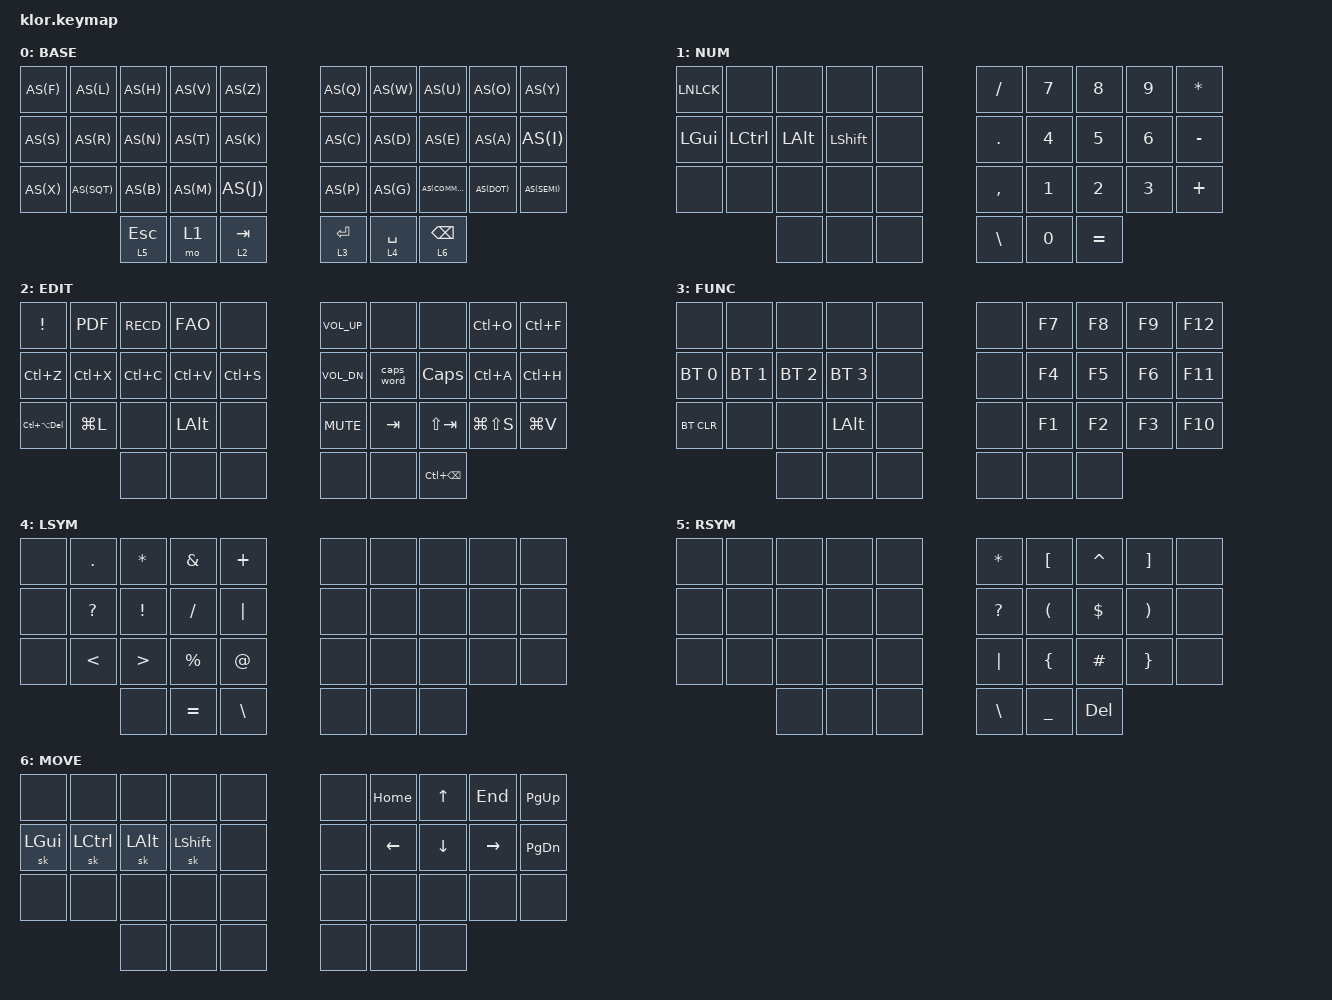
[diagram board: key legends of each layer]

//                     █         █    █            ▄▄▄▀▀▀▀▀▀▄▄▄        █▀▀▀▀▀▀▀▀▀▀█
//                     █        █     █          ▄▀            ▀▄      █          █
//                     █       █      █        ▄▀                ▀▄    █          █
//                     █      █       █        █                  █    █          █
//                     █     █        █       █                    █   █          █
//                     █    █         █       █                    █   █▄▄▄▄▄▄▄▄▄▄█
//                     █   █ █        █       █                    █   █      █
//                     █  █   █       █        █                  █    █       █
//                     █ █     █      █        ▀▄                ▄▀    █        █
//                     ██       █     █          ▀▄            ▄▀      █         █
//                     █         █    █▄▄▄▄▄▄▄▄    ▀▀▀▄▄▄▄▄▄▀▀▀        █          █
//
// ▄▄▄▄▄▄▄▄▄▄▄▄▄▄▄▄▄▄▄▄▄▄▄▄▄▄▄▄▄▄▄▄▄▄▄▄▄▄▄▄▄▄▄▄▄▄▄▄▄▄▄▄▄▄▄▄▄▄▄▄▄▄▄▄▄▄▄▄▄▄▄▄▄▄▄▄▄▄▄▄▄▄▄▄▄▄▄▄▄▄▄▄▄▄▄▄▄▄▄▄▄▄▄▄▄▄▄▄▄▄▄▄▄▄▄▄▄▄▄▄▄▄▄▄▄
       
#include <behaviors.dtsi>
#include <dt-bindings/zmk/keys.h>
#include <dt-bindings/zmk/bt.h>
#include <dt-bindings/zmk/outputs.h>
#include <dt-bindings/zmk/ext_power.h>
#include <dt-bindings/zmk/rgb.h>


#define BASE 0
#define NUM  1
#define FUNC 2
#define EDIT 3
#define LSYM 4
#define RSYM 5
#define MOVE 6
#define AS(keycode) &as LS(keycode) keycode   // Autoshift Macro


&lt {
    tapping_term_ms = <200>;
    quick_tap_ms = <150>;
    flavor = "tap-preferred";
};

/ {
    behaviors {
        as: auto_shift {
            compatible = "zmk,behavior-hold-tap";
            #binding-cells = <2>;
            tapping_term_ms = <200>;
            quick_tap_ms = <150>;
            flavor = "tap-preferred";
            bindings = <&kp>, <&kp>;
        };
    };



        keymap {
                compatible = "zmk,keymap";


// ▄▄▄▄▄▄▄▄▄▄▄▄▄▄▄▄▄▄▄▄▄▄▄▄▄▄▄▄▄▄▄▄▄▄▄▄▄▄▄▄▄▄▄▄▄▄▄▄▄▄▄▄▄▄▄▄▄▄▄▄▄▄▄▄▄▄▄▄▄▄▄▄▄▄▄▄▄▄▄▄▄▄▄▄▄▄▄▄▄▄▄▄▄▄▄▄▄▄▄▄▄▄▄▄▄▄▄▄▄▄▄▄▄▄▄▄▄▄▄▄▄▄▄▄▄


                BASE {
// ┌───────────────────────────────────────────────────────────┐
display-name = "BASE"                                          ;        
// └───────────────────────────────────────────────────────────┘
/*  ┌─────────┬─────────┬─────────┬─────────┬─────────┐                    ┌─────────┬─────────┬─────────┬─────────┬─────────┐
    │    F    │    L    │    H    │    V    │    Z    │                    │    Q    |    W    |    U    |    O    |    Y    │   
    |─────────┼─────────┼─────────┼─────────┼─────────┤                    ├─────────┼─────────┼─────────┼─────────┼─────────|
    │    S    |    R    |    N    |    T    |    K    │                    │    C    |    D    |    E    |    A    |    I    │
    |─────────┼─────────┼─────────┼─────────┼─────────┤╭────────╮╭────────╮├─────────┼─────────┼─────────┼─────────┼─────────|
    │    X    |    '    |    B    |    M    |    J    ││  ENC2  ││  ENC1  ││    K    │    M    │    ,    │    .    │    /    │
    |─────────┴─────────┼─────────┼─────────┼─────────┼╰────────╯╰────────╯┼─────────┼─────────┼─────────┼─────────┴─────────┴
                        │ L5/ESC  |   L1    | L3/TAB  │         ││         │  ENTER  │  RAISE  │  BSPCE  │  
                        └─────────┴─────────┴─────────┴─────────┘└─────────┴─────────┴─────────┴─────────┘ */ 
 bindings = <
        AS(F) AS(L)   AS(H) AS(V) AS(Z)   AS(Q) AS(W)  AS(U)     AS(O)   AS(Y)   
        AS(S) AS(R)   AS(N) AS(T) AS(K)   AS(C) AS(D)  AS(E)     AS(A)   AS(I)   
        AS(X) AS(SQT) AS(B) AS(M) AS(J)   AS(P) AS(G)  AS(COMMA) AS(DOT) AS(SEMI) 
              &lt 5 ESC &mo 1 &lt 2 TAB  &lt 3 ENTER &lt 4 SPACE &lt 6 BSPC    
                        >;
                };

// ▄▄▄▄▄▄▄▄▄▄▄▄▄▄▄▄▄▄▄▄▄▄▄▄▄▄▄▄▄▄▄▄▄▄▄▄▄▄▄▄▄▄▄▄▄▄▄▄▄▄▄▄▄▄▄▄▄▄▄▄▄▄▄▄▄▄▄▄▄▄▄▄▄▄▄▄▄▄▄▄▄▄▄▄▄▄▄▄▄▄▄▄▄▄▄▄▄▄▄▄▄▄▄▄▄▄▄▄▄▄▄▄▄▄▄▄▄▄▄▄▄▄▄▄▄


                NUM {
// ┌───────────────────────────────────────────────────────────┐
display-name = "NUM"                                           ;      
// └───────────────────────────────────────────────────────────┘
/*  ┌─────────┬─────────┬─────────┬─────────┬─────────┐                    ┌─────────┬─────────┬─────────┬─────────┬─────────┐
    │   NLK   │         │         │         │         │                    │    /    |    7    |    8    |    9    |    *    │   
    |─────────┼─────────┼─────────┼─────────┼─────────┤                    ├─────────┼─────────┼─────────┼─────────┼─────────|
    │   GUI   |   CTL   |   ALT   |   SFT   │         │                    │    .    |    4    |    5    |    6    |    -    │
    |─────────┼─────────┼─────────┼─────────┼─────────┤╭────────╮╭────────╮├─────────┼─────────┼─────────┼─────────┼─────────|
    │         │         |         |         |         ││  ENC2  ││  ENC1  ││    ,    |    1    |    2    |    3    |    +    │
    |─────────┴─────────┼─────────┼─────────┼─────────┼╰────────╯╰────────╯┼─────────┼─────────┼─────────┼─────────┴─────────┴
                        │         |         |         |         ││         │    \    |    0    |    =    │  
                        └─────────┴─────────┴─────────┴─────────┘└─────────┴─────────┴─────────┴─────────┘ */ 
 bindings = <
        &kp LNLCK &none     &none    &none       &none   &kp SLASH  &kp N7  &kp N8  &kp N9  &kp STAR   
        &kp LGUI  &kp LCTRL &kp LALT &kp LSHIFT  &none   &kp DOT    &kp N4  &kp N5  &kp N6  &kp MINUS  
        &none     &none     &none    &none       &none   &kp COMMA  &kp N1  &kp N2  &kp N3  &kp PLUS  
                            &none    &none       &none   &kp BSLH   &kp N0  &kp EQUAL
                        >;
                };

// ▄▄▄▄▄▄▄▄▄▄▄▄▄▄▄▄▄▄▄▄▄▄▄▄▄▄▄▄▄▄▄▄▄▄▄▄▄▄▄▄▄▄▄▄▄▄▄▄▄▄▄▄▄▄▄▄▄▄▄▄▄▄▄▄▄▄▄▄▄▄▄▄▄▄▄▄▄▄▄▄▄▄▄▄▄▄▄▄▄▄▄▄▄▄▄▄▄▄▄▄▄▄▄▄▄▄▄▄▄▄▄▄▄▄▄▄▄▄▄▄▄▄▄▄▄


                EDIT {
// ┌───────────────────────────────────────────────────────────┐
display-name = "EDIT"                                          ;      
// └───────────────────────────────────────────────────────────┘
/*  ┌─────────┬─────────┬─────────┬─────────┬─────────┐                    ┌─────────┬─────────┬─────────┬─────────┬─────────┐
    │  AFKM   |   PDF   |  RECD   |   FAO   |         │                    │  VOLU   |         |         |  CTLO   |  FIND   │   
    |─────────┼─────────┼─────────┼─────────┼─────────┤                    ├─────────┼─────────┼─────────┼─────────┼─────────|
    │  UNDO   |   CUT   |  COPY   |  PASTE  |  SAVE   │                    │  VOLD   |   CW    |  CAPS   |   ALL   |  REPL   │
    |─────────┼─────────┼─────────┼─────────┼─────────┤╭────────╮╭────────╮├─────────┼─────────┼─────────┼─────────┼─────────|
    │   CAD   |   LOCK  |         |   ALT   |         ││  ENC2  ││  ENC1  ││  MUTE   |   TAB   |  STAB   |   PIC   |  CLIP   │
    |─────────┴─────────┼─────────┼─────────┼─────────┼╰────────╯╰────────╯┼─────────┼─────────┼─────────┼─────────┴─────────┴
                        │         |         |         |         ││         │         │         │  CBCK   │  
                        └─────────┴─────────┴─────────┴─────────┘└─────────┴─────────┴─────────┴─────────┘ */ 
 bindings = <
        &kp EXCL        &PDF      &RECD     &FAO      &none      &kp C_VOL_UP &none      &none       &kp LC(O)     &kp LC(F) 
        &kp LC(Z)       &kp LC(X) &kp LC(C) &kp LC(V) &kp LC(S)  &kp C_VOL_DN &caps_word &kp CAPS    &kp LC(A)     &kp LC(H) 
        &kp LC(LA(DEL)) &kp LG(L) &none     &kp LALT  &none      &kp C_MUTE   &kp TAB    &kp LS(TAB) &kp LG(LS(S)) &kp LG(V) 
                                  &none     &none     &none      &none        &none      &kp LC(BSPC)
                        >;
                };

// ▄▄▄▄▄▄▄▄▄▄▄▄▄▄▄▄▄▄▄▄▄▄▄▄▄▄▄▄▄▄▄▄▄▄▄▄▄▄▄▄▄▄▄▄▄▄▄▄▄▄▄▄▄▄▄▄▄▄▄▄▄▄▄▄▄▄▄▄▄▄▄▄▄▄▄▄▄▄▄▄▄▄▄▄▄▄▄▄▄▄▄▄▄▄▄▄▄▄▄▄▄▄▄▄▄▄▄▄▄▄▄▄▄▄▄▄▄▄▄▄▄▄▄▄▄


                FUNC {
// ┌───────────────────────────────────────────────────────────┐
display-name = "FUNC"                                          ;
// └───────────────────────────────────────────────────────────┘
/*  ┌─────────┬─────────┬─────────┬─────────┬─────────┐                    ┌─────────┬─────────┬─────────┬─────────┬─────────┐
    │         │         │         │         │         │                    │         |   F7    |   F8    |   F9    |   F12   │   
    |─────────┼─────────┼─────────┼─────────┼─────────┤                    ├─────────┼─────────┼─────────┼─────────┼─────────|
    │   BT1   |   BT2   |   BT3   |   BT4   │         │                    │         |   F4    |   F5    |   F6    |   F11   │
    |─────────┼─────────┼─────────┼─────────┼─────────┤╭────────╮╭────────╮├─────────┼─────────┼─────────┼─────────┼─────────|
    │  BTCLR  |         |         |   ALT   |         ││  ENC2  ││  ENC1  ││         |   F1    |   F2    |   F3    |   F10   │
    |─────────┴─────────┼─────────┼─────────┼─────────┼╰────────╯╰────────╯┼─────────┼─────────┼─────────┼─────────┴─────────┴
                        │         |         |         |         ││         │         |         |         │  
                        └─────────┴─────────┴─────────┴─────────┘└─────────┴─────────┴─────────┴─────────┘ */ 
 bindings = <
        &none        &none        &none        &none        &none   &none  &kp F7 &kp F8 &kp F9 &kp F12
        &bt BT_SEL 0 &bt BT_SEL 1 &bt BT_SEL 2 &bt BT_SEL 3 &none   &none  &kp F4 &kp F5 &kp F6 &kp F11
        &bt BT_CLR   &none        &none        &kp LALT     &none   &none  &kp F1 &kp F2 &kp F3 &kp F10
                                  &none        &none        &none   &none  &none  &none
                        >;
        };

// ▄▄▄▄▄▄▄▄▄▄▄▄▄▄▄▄▄▄▄▄▄▄▄▄▄▄▄▄▄▄▄▄▄▄▄▄▄▄▄▄▄▄▄▄▄▄▄▄▄▄▄▄▄▄▄▄▄▄▄▄▄▄▄▄▄▄▄▄▄▄▄▄▄▄▄▄▄▄▄▄▄▄▄▄▄▄▄▄▄▄▄▄▄▄▄▄▄▄▄▄▄▄▄▄▄▄▄▄▄▄▄▄▄▄▄▄▄▄▄▄▄▄▄▄▄


                LSYM {
// ┌───────────────────────────────────────────────────────────┐
display-name = "LSYM"                                          ;
// └───────────────────────────────────────────────────────────┘
/*  ┌─────────┬─────────┬─────────┬─────────┬─────────┐                    ┌─────────┬─────────┬─────────┬─────────┬─────────┐
    │         │    .    │    *    |    &    |    +    │                    │         |         |         |         |         |   
    |─────────┼─────────┼─────────┼─────────┼─────────┤                    ├─────────┼─────────┼─────────┼─────────┼─────────|
    │         |    ?    |    !    |    /    |    |    │                    │         |         |         |         |         |
    |─────────┼─────────┼─────────┼─────────┼─────────┤╭────────╮╭────────╮├─────────┼─────────┼─────────┼─────────┼─────────|
    │         |    <    |    >    |    %    |    @    ││  ENC2  ││  ENC1  ││         |         |         |         |         |
    |─────────┴─────────┼─────────┼─────────┼─────────┼╰────────╯╰────────╯┼─────────┼─────────┼─────────┼─────────┴─────────┴
                        │         |    =    |    \    |         ││         │         |         |         │  
                        └─────────┴─────────┴─────────┴─────────┘└─────────┴─────────┴─────────┴─────────┘ */ 
 bindings = <
        &none  &kp DOT   &kp STAR &kp AMPS  &kp PLUS      &none  &none  &none  &none  &none
        &none  &kp QMARK &kp EXCL &kp SLASH &kp PIPE      &none  &none  &none  &none  &none
        &none  &kp LT    &kp GT   &kp PRCNT &kp AT        &none  &none  &none  &none  &none
                         &none    &kp EQUAL &kp BSLH      &none  &none  &none
                        >;
        };

// ▄▄▄▄▄▄▄▄▄▄▄▄▄▄▄▄▄▄▄▄▄▄▄▄▄▄▄▄▄▄▄▄▄▄▄▄▄▄▄▄▄▄▄▄▄▄▄▄▄▄▄▄▄▄▄▄▄▄▄▄▄▄▄▄▄▄▄▄▄▄▄▄▄▄▄▄▄▄▄▄▄▄▄▄▄▄▄▄▄▄▄▄▄▄▄▄▄▄▄▄▄▄▄▄▄▄▄▄▄▄▄▄▄▄▄▄▄▄▄▄▄▄▄▄▄


                RSYM {
// ┌───────────────────────────────────────────────────────────┐
display-name = "RSYM"                                          ;
// └───────────────────────────────────────────────────────────┘
/*  ┌─────────┬─────────┬─────────┬─────────┬─────────┐                    ┌─────────┬─────────┬─────────┬─────────┬─────────┐
    │         |         |         |         |         |                    │    *    |    [    |    ^    |    ]    |         |         |         |         |   
    |─────────┼─────────┼─────────┼─────────┼─────────┤                    ├─────────┼─────────┼─────────┼─────────┼─────────|
    │         |         |         |         |         |                    │    ?    |    (    |    $    |    )    |         |
    |─────────┼─────────┼─────────┼─────────┼─────────┤╭────────╮╭────────╮├─────────┼─────────┼─────────┼─────────┼─────────|
    │         |         |         |         |         |│  ENC2  ││  ENC1  ││    |    |    {    |    #    |    }    |         |
    |─────────┴─────────┼─────────┼─────────┼─────────┼╰────────╯╰────────╯┼─────────┼─────────┼─────────┼─────────┴─────────┴
                        │         |         |         |         ││         │    \    |    _    |   DEL   │  
                        └─────────┴─────────┴─────────┴─────────┘└─────────┴─────────┴─────────┴─────────┘ */ 
 bindings = <
        &none  &none  &none  &none  &none   &kp STAR  &kp LBKT  &kp CARET &kp RBKT &none
        &none  &none  &none  &none  &none   &kp QMARK &kp LPAR  &kp DLLR  &kp RPAR &none
        &none  &none  &none  &none  &none   &kp PIPE  &kp LBRC  &kp HASH  &kp RBRC &none
                      &none  &none  &none   &kp BSLH &kp UNDER &kp DEL
                        >;
        };

// ▄▄▄▄▄▄▄▄▄▄▄▄▄▄▄▄▄▄▄▄▄▄▄▄▄▄▄▄▄▄▄▄▄▄▄▄▄▄▄▄▄▄▄▄▄▄▄▄▄▄▄▄▄▄▄▄▄▄▄▄▄▄▄▄▄▄▄▄▄▄▄▄▄▄▄▄▄▄▄▄▄▄▄▄▄▄▄▄▄▄▄▄▄▄▄▄▄▄▄▄▄▄▄▄▄▄▄▄▄▄▄▄▄▄▄▄▄▄▄▄▄▄▄▄▄


                MOVE {
// ┌───────────────────────────────────────────────────────────┐
display-name = "MOVE"                                          ;
// └───────────────────────────────────────────────────────────┘
/*  ┌─────────┬─────────┬─────────┬─────────┬─────────┐                    ┌─────────┬─────────┬─────────┬─────────┬─────────┐
    │         |         |         |         |         |                    │  HOME   |   UP    |   END   |  PGUP   |         |         |         |         |   
    |─────────┼─────────┼─────────┼─────────┼─────────┤                    ├─────────┼─────────┼─────────┼─────────┼─────────|
    │         |  OGUI   |  OCTL   |  OALT   |  OSFT   |                    │  LEFT   |  DOWN   |  RIGHT  |  PGDN   |         |
    |─────────┼─────────┼─────────┼─────────┼─────────┤╭────────╮╭────────╮├─────────┼─────────┼─────────┼─────────┼─────────|
    │         |         |         |         |         |│  ENC2  ││  ENC1  ││         |         |         |         |         |
    |─────────┴─────────┼─────────┼─────────┼─────────┼╰────────╯╰────────╯┼─────────┼─────────┼─────────┼─────────┴─────────┴
                        │         |         |         |         ││         │         |         |         │  
                        └─────────┴─────────┴─────────┴─────────┘└─────────┴─────────┴─────────┴─────────┘ */ 
 bindings = <
        &none    &none     &none    &none      &none   &none  &kp HOME &kp UP   &kp END   &kp PG_UP
        &sk LGUI &sk LCTRL &sk LALT &sk LSHIFT &none   &none  &kp LEFT &kp DOWN &kp RIGHT &kp PG_DN
        &none    &none     &none    &none      &none   &none  &none    &none    &none     &none
                           &none    &none      &none   &none  &none    &none
                        >;
                };
        };
};



// MACROS

/ {
    macros {
        RECD: RECD {
            compatible = "zmk,behavior-macro";
            #binding-cells = <0>;
            bindings
                = <&macro_tap &kp CAPS &kp R &kp E &kp C &kp E &kp I &kp V &kp E &kp D &kp CAPS &kp ENTER>
                ;
        };

        FAO: FAO {
            compatible = "zmk,behavior-macro";
            #binding-cells = <0>;
            bindings
                = <&macro_tap &kp CAPS &kp T &kp X &kp D &kp M &kp V &kp MINUS &kp F &kp A &kp O &kp CAPS>
                ;
        };

        PDF: PDF {
            compatible = "zmk,behavior-macro";
            #binding-cells = <0>;
            bindings
                = <&macro_press &kp LALT>
                , <&macro_tap &kp V &kp P &kp P>
                , <&macro_release &kp LALT>
                , <&macro_press &kp LGUI>
                , <&macro_tap &kp UP>
                , <&macro_release &kp LGUI>
                ;
        };
    };
};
